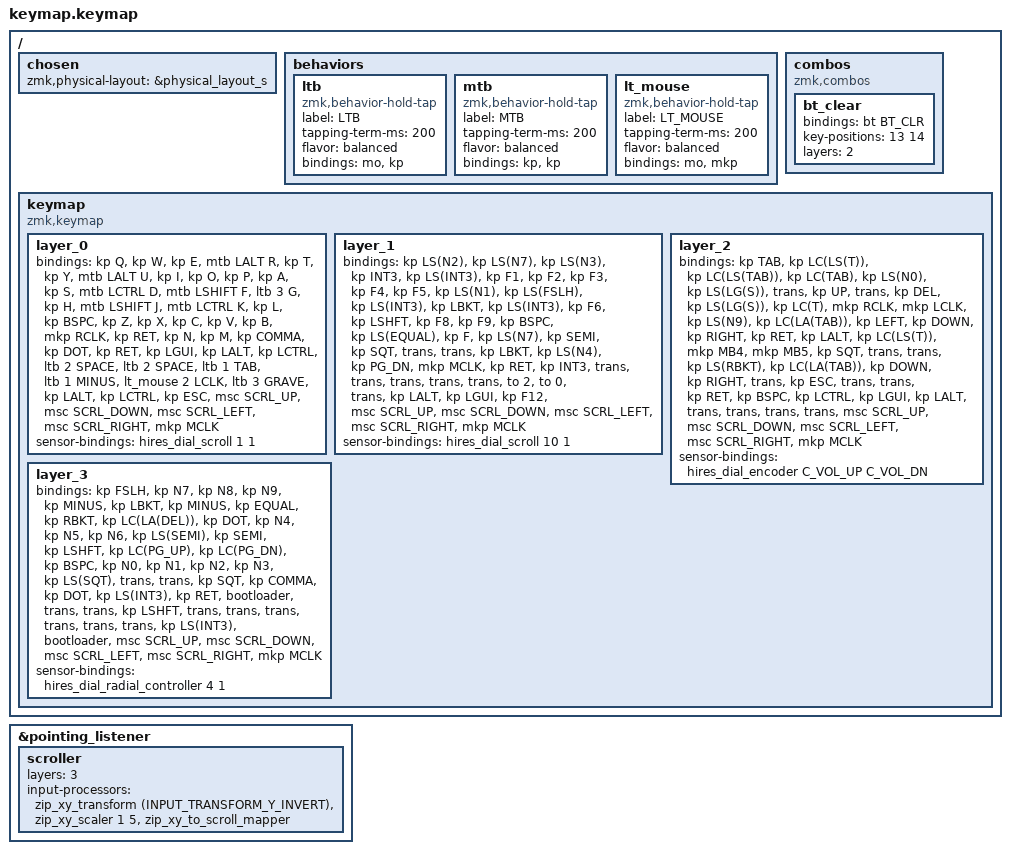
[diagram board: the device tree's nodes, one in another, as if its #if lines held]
/*
 * torabo-tsuki LP (S size) keymap — 直接ビルド用 (44 bindings 版)
 *
 * Keyball39 の配置を移植したもの。config/keymap.keymap としてフォークに
 * 入れて GitHub Actions でビルドする前提のファイル。
 * chosen で physical_layout_s を選択し、各レイヤーは S の実キー44個分の
 * bindings のみを持つ (L 版 66 個から実在キーのみを抽出)。
 * 実機確認 (2026-11-21): S は42スイッチ (左20/右22)。左下段の定義位置
 * 34・35番 (L 版 index 55・56) はスイッチが無く、左親指は36・37番の2個。
 * そのため Space は35番 (ダミー) と36番 (実キー) の両方に置き、
 * Tab は37番 (実キー) に置く。左下段の実キーは 32・33・36・37番。
 * 元の 66 個版は keymap.keymap (Keymap-Editor 用) を参照。
 */

#include <behaviors.dtsi>
#include <input/processors.dtsi>
#include <dt-bindings/zmk/bt.h>
#include <dt-bindings/zmk/input_transform.h>
#include <dt-bindings/zmk/keys.h>
#include <dt-bindings/zmk/outputs.h>
#include <dt-bindings/zmk/pointing.h>

/* S サイズを選択 (デフォルトの L から上書き) */
/
{
    chosen {
        zmk,physical-layout = &physical_layout_s;
    };
};

#if defined(TORABO_TSUKI_LP_INPUT_HIRES_DIAL)
#include <behaviors/hires_dial.dtsi>
#endif

/ {
    behaviors {
        /* タップ=マウスクリック、長押し=レイヤー のための hold-tap
           (純正の &ltb はタップ側にマウスボタンを置けないため) */
        /* Keyball(QMK) の判定方式に寄せた hold-tap: balanced / 200ms
           (QMK は TAPPING_TERM 未定義 = 既定 200ms、判定は離すタイミング基準。
            ZMK 既定の hold-preferred は「他のキーを押した瞬間に長押し判定」になるため、
            Keyball と同じ感覚にするには balanced が最も近い) */
        ltb: ltb {
            compatible = "zmk,behavior-hold-tap";
            label = "LTB";
            #binding-cells = <2>;
            tapping-term-ms = <200>;
            flavor = "balanced";
            bindings = <&mo>, <&kp>;
        };

        mtb: mtb {
            compatible = "zmk,behavior-hold-tap";
            label = "MTB";
            #binding-cells = <2>;
            tapping-term-ms = <200>;
            flavor = "balanced";
            bindings = <&kp>, <&kp>;
        };

        lt_mouse: lt_mouse {
            compatible = "zmk,behavior-hold-tap";
            label = "LT_MOUSE";
            #binding-cells = <2>;
            tapping-term-ms = <200>;
            flavor = "balanced";
            bindings = <&mo>, <&mkp>;
        };
    };

    combos {
        compatible = "zmk,combos";

        bt_clear {
            bindings = <&bt BT_CLR>;
            key-positions = <13 14>;
            layers = <2>;
        };
    };

    keymap {
        compatible = "zmk,keymap";

        /* Layer 0: Keyball の Layer 0 と同じ指使い
           R/D/F/G などは Keyball と同じモッドタップ・レイヤータップ */
        layer_0 {
            bindings = <
&kp Q &kp W &kp E &mtb LALT R &kp T &kp Y &mtb LALT U &kp I &kp O &kp P
&kp A &kp S &mtb LCTRL D &mtb LSHIFT F &ltb 3 G &kp H &mtb LSHIFT J &mtb LCTRL K &kp L &kp BSPC
&kp Z &kp X &kp C &kp V &kp B &mkp RCLK &kp RET &kp N &kp M &kp COMMA &kp DOT &kp RET
&kp LGUI &kp LALT &kp LCTRL &ltb 2 SPACE &ltb 2 SPACE &ltb 1 TAB &ltb 1 MINUS &lt_mouse 2 LCLK &ltb 3 GRAVE &kp LALT &kp LCTRL &kp ESC
#if defined(TORABO_TSUKI_LP_KSCAN_4_DIRECTION_SWITCH)
&msc SCRL_UP &msc SCRL_DOWN &msc SCRL_LEFT &msc SCRL_RIGHT &mkp MCLK
#elif defined(TORABO_TSUKI_LP_INPUT_HIRES_DIAL)
&mkp MCLK
#endif

            >;
        };

        /* Layer 1: 記号・Fキー (Keyball の Layer 1)
           (*S+xx) はチートシートの表記どおり Shift+xx の同時押しとして再現 */
        layer_1 {
            bindings = <
&kp LS(N2) &kp LS(N7) &kp LS(N3) &kp INT3 &kp LS(INT3) &kp F1 &kp F2 &kp F3 &kp F4 &kp F5
&kp LS(N1) &kp LS(FSLH) &kp LS(INT3) &kp LBKT &kp LS(INT3) &kp F6 &kp LSHFT &kp F8 &kp F9 &kp BSPC
&kp LS(EQUAL) &kp F &kp LS(N7) &kp SEMI &kp SQT &trans &trans &kp LBKT &kp LS(N4) &kp PG_DN &mkp MCLK &kp RET
&kp INT3 &trans &trans &trans &trans &trans &to 2 &to 0 &trans &kp LALT &kp LGUI &kp F12
#if defined(TORABO_TSUKI_LP_KSCAN_4_DIRECTION_SWITCH)
&msc SCRL_UP &msc SCRL_DOWN &msc SCRL_LEFT &msc SCRL_RIGHT &mkp MCLK
#elif defined(TORABO_TSUKI_LP_INPUT_HIRES_DIAL)
&mkp MCLK
#endif

            >;
        };

        /* Layer 2: マウス・ショートカット (Keyball の Layer 2) */
        layer_2 {
            bindings = <
&kp TAB &kp LC(LS(T)) &kp LC(LS(TAB)) &kp LC(TAB) &kp LS(N0) &kp LS(LG(S)) &trans &kp UP &trans &kp DEL
&kp LS(LG(S)) &kp LC(T) &mkp RCLK &mkp LCLK &kp LS(N9) &kp LC(LA(TAB)) &kp LEFT &kp DOWN &kp RIGHT &kp RET
&kp LALT &kp LC(LS(T)) &mkp MB4 &mkp MB5 &kp SQT &trans &trans &kp LS(RBKT) &kp LC(LA(TAB)) &kp DOWN &kp RIGHT &trans
&kp ESC &trans &trans &kp RET &kp BSPC &kp LCTRL &kp LGUI &kp LALT &trans &trans &trans &trans
#if defined(TORABO_TSUKI_LP_KSCAN_4_DIRECTION_SWITCH)
&msc SCRL_UP &msc SCRL_DOWN &msc SCRL_LEFT &msc SCRL_RIGHT &mkp MCLK
#elif defined(TORABO_TSUKI_LP_INPUT_HIRES_DIAL)
&kp C_MUTE
#endif

            >;
        };

        /* Layer 3: 数字 (Keyball の Layer 3) */
        layer_3 {
            bindings = <
&kp FSLH &kp N7 &kp N8 &kp N9 &kp MINUS &kp LBKT &kp MINUS &kp EQUAL &kp RBKT &kp LC(LA(DEL))
&kp DOT &kp N4 &kp N5 &kp N6 &kp LS(SEMI) &kp SEMI &kp LSHFT &kp LC(PG_UP) &kp LC(PG_DN) &kp BSPC
&kp N0 &kp N1 &kp N2 &kp N3 &kp LS(SQT) &trans &trans &kp SQT &kp COMMA &kp DOT &kp LS(INT3) &kp RET
&bootloader &trans &trans &kp LSHFT &trans &trans &trans &trans &trans &trans &kp LS(INT3) &bootloader
#if defined(TORABO_TSUKI_LP_KSCAN_4_DIRECTION_SWITCH)
&msc SCRL_UP &msc SCRL_DOWN &msc SCRL_LEFT &msc SCRL_RIGHT &mkp MCLK
#elif defined(TORABO_TSUKI_LP_INPUT_HIRES_DIAL)
&hires_dial_radial_controller_button
#endif

            >;
        };
    };
};

/* レイヤー3が出ている間はトラックボールをスクロール化する
   (Keyball の「レイヤーキーを押している間ボールがスクロール」の仕様に
    合わせた固定機能。エディタの編集対象ではない)
   pointing_listener のレイヤー別 input-processors 上書き。
   Y軸を反転して「ボールを奥に転がす = 上にスクロール」に合わせ、
   速度は生の移動量の 1/5 に落とす */
&pointing_listener {
    scroller {
        layers = <3>;
        input-processors = <&zip_xy_transform (INPUT_TRANSFORM_Y_INVERT)>, <&zip_xy_scaler 1 5>, <&zip_xy_to_scroll_mapper>;
    };
};

#if defined(TORABO_TSUKI_LP_INPUT_HIRES_DIAL)
&{/keymap/layer_0} {
    sensor-bindings = <&hires_dial_scroll 1 1>;
};

&{/keymap/layer_1} {
    sensor-bindings = <&hires_dial_scroll 10 1>;
};

&{/keymap/layer_2} {
    sensor-bindings = <&hires_dial_encoder C_VOL_UP C_VOL_DN>;
};

&{/keymap/layer_3} {
    /* Quarter-speed Radial Controller motion: output/input = 1/4. */
    sensor-bindings = <&hires_dial_radial_controller 4 1>;
};
#endif
